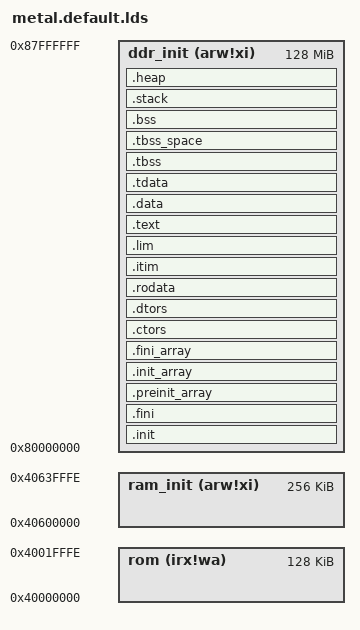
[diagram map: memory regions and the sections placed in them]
/* Copyright (c) 2020 SiFive Inc. */
/* SPDX-License-Identifier: Apache-2.0 */
OUTPUT_ARCH("riscv")

/* Default Linker Script
 *
 * This is the default linker script for all Freedom Metal applications.
 */

ENTRY(_enter)

MEMORY
{
    rom (irx!wa) : ORIGIN = 0x40000000, LENGTH = 0x1ffff
    ram_init (arw!xi) : ORIGIN = 0x40600000, LENGTH = 0x3ffff
    ddr_init (arw!xi) : ORIGIN = 0x80000000, LENGTH = 0x8000000
    /* ram (arw!xi) : ORIGIN = 0x40640000, LENGTH = 0x3bffff */
    /* ddr (arw!xi) : ORIGIN = 0x80040000, LENGTH = 0x7ffbffff */
}

PHDRS
{
    rom PT_LOAD;
    ram_init PT_LOAD;
    ddr_init PT_LOAD;
    /* ddr PT_LOAD; */
    /* tls PT_TLS; */
    /* ram PT_LOAD; */
    text PT_LOAD;
}

SECTIONS
{
    /* Each hart is allocated its own stack of size __stack_size. This value
     * can be overriden at build-time by adding the following to CFLAGS:
     *
     *     -Xlinker --defsym=__stack_size=0xf00
     *
     * where 0xf00 can be replaced with a multiple of 16 of your choice.
     *
     * __stack_size is PROVIDE-ed as a symbol so that initialization code
     * initializes the stack pointers for each hart at the right offset from
     * the _sp symbol.
     */
    __stack_size = DEFINED(__stack_size) ? __stack_size : 0x2000000;
    PROVIDE(__stack_size = __stack_size);

    /* The size of the heap can be overriden at build-time by adding the
     * following to CFLAGS:
     *
     *     -Xlinker --defsym=__heap_size=0xf00
     *
     * where 0xf00 can be replaced with the value of your choice.
     *
     * Altertatively, the heap can be grown to fill the entire remaining region
     * of RAM by adding the following to CFLAGS:
     *
     *     -Xlinker --defsym=__heap_max=1
     *
     * Note that depending on the memory layout, the bitness (32/64bit) of the
     * target, and the code model in use, this might cause a relocation error.
     */
    __heap_size = DEFINED(__heap_size) ? __heap_size : 0x2000000;

    /* The boot hart sets which hart runs the pre-main initialization routines,
     * including copying .data into RAM, zeroing the BSS region, running
     * constructors, etc. After initialization, the boot hart is also the only
     * hart which runs application code unless the application overrides the
     * secondary_main() function to start execution on secondary harts.
     */
    PROVIDE(__metal_boot_hart = 0);

    /* The chicken bit is used by pre-main initialization to enable/disable
     * certain core features */
    PROVIDE(__metal_chicken_bit = 1);

    .init : {
        /* The _enter symbol is placed in the .text.metal.init.enter section
         * and must be placed at the beginning of the program */
        KEEP (*(.text.metal.init.enter))
        KEEP (*(.text.metal.init.*))
        KEEP (*(SORT_NONE(.init)))
        KEEP (*(.text.libgloss.start))
    } >ddr_init :ddr_init

    .fini : {
        KEEP (*(SORT_NONE(.fini)))
    } >ddr_init :ddr_init

    .preinit_array : ALIGN(8) {
        PROVIDE_HIDDEN (__preinit_array_start = .);
        KEEP (*(.preinit_array))
        PROVIDE_HIDDEN (__preinit_array_end = .);
    } >ddr_init :ddr_init

    .init_array : ALIGN(8) {
        PROVIDE_HIDDEN (__init_array_start = .);
        KEEP (*(SORT_BY_INIT_PRIORITY(.init_array.*) SORT_BY_INIT_PRIORITY(.ctors.*)))
        KEEP (*(.init_array EXCLUDE_FILE (*crtbegin.o *crtbegin?.o *crtend.o *crtend?.o ) .ctors))
        PROVIDE_HIDDEN (__init_array_end = .);
        PROVIDE_HIDDEN ( metal_constructors_start = .);
        KEEP (*(SORT_BY_INIT_PRIORITY(.metal.init_array.*)));
        KEEP (*(.metal.init_array));
        PROVIDE_HIDDEN ( metal_constructors_end = .);
    } >ddr_init :ddr_init

    .fini_array : ALIGN(8) {
        PROVIDE_HIDDEN (__fini_array_start = .);
        KEEP (*(SORT_BY_INIT_PRIORITY(.fini_array.*) SORT_BY_INIT_PRIORITY(.dtors.*)))
        KEEP (*(.fini_array EXCLUDE_FILE (*crtbegin.o *crtbegin?.o *crtend.o *crtend?.o ) .dtors))
        PROVIDE_HIDDEN (__fini_array_end = .);
        PROVIDE_HIDDEN ( metal_destructors_start = .);
        KEEP (*(SORT_BY_INIT_PRIORITY(.metal.fini_array.*)));
        KEEP (*(.metal.fini_array));
        PROVIDE_HIDDEN ( metal_destructors_end = .);
    } >ddr_init :ddr_init


    .ctors : {
        KEEP (*crtbegin.o(.ctors))
        KEEP (*crtbegin?.o(.ctors))
        KEEP (*(EXCLUDE_FILE (*crtend.o *crtend?.o ) .ctors))
        KEEP (*(SORT(.ctors.*)))
        KEEP (*(.ctors))
        KEEP (*(.metal.ctors .metal.ctors.*))
    } >ddr_init :ddr_init

    .dtors : {
        KEEP (*crtbegin.o(.dtors))
        KEEP (*crtbegin?.o(.dtors))
        KEEP (*(EXCLUDE_FILE (*crtend.o *crtend?.o ) .dtors))
        KEEP (*(SORT(.dtors.*)))
        KEEP (*(.dtors))
        KEEP (*(.metal.dtors .metal.dtors.*))
    } >ddr_init : ddr_init

    .rodata : {
        *(.rdata)
        *(.rodata .rodata.*)
        *(.gnu.linkonce.r.*)
        . = ALIGN(8);
        *(.srodata.cst16)
        *(.srodata.cst8)
        *(.srodata.cst4)
        *(.srodata.cst2)
        *(.srodata .srodata.*)
    } >ddr_init :ddr_init

    .itim : ALIGN(8) {
        *(.itim .itim.*)
    } >ddr_init :ddr_init

    PROVIDE( metal_segment_itim_source_start = LOADADDR(.itim) );
    PROVIDE( metal_segment_itim_target_start = ADDR(.itim) );
    PROVIDE( metal_segment_itim_target_end = ADDR(.itim) + SIZEOF(.itim) );
    
    .lim : ALIGN(8) {
        *(.lim .lim.*)
    } >ddr_init :ddr_init

    PROVIDE( metal_segment_lim_source_start = LOADADDR(.lim) );
    PROVIDE( metal_segment_lim_target_start = ADDR(.lim) );
    PROVIDE( metal_segment_lim_target_end = ADDR(.lim) + SIZEOF(.lim) );
    
    .text : {
        *(.text.unlikely .text.unlikely.*)
        *(.text.startup .text.startup.*)
        *(.text .text.*)
        *(.gnu.linkonce.t.*)
    } >ddr_init :text

    .data : ALIGN(8) {
        *(.data .data.*)
        *(.gnu.linkonce.d.*)
        . = ALIGN(8);
        PROVIDE( __global_pointer$ = . + 0x800 );
        *(.sdata .sdata.* .sdata2.*)
        *(.gnu.linkonce.s.*)
    } >ddr_init :ddr_init

    .tdata : ALIGN(8) {
        PROVIDE( __tls_base = . );
	*(.tdata .tdata.* .gnu.linkonce.td.*)
    } >ddr_init :ddr_init

    PROVIDE( __tdata_source = LOADADDR(.tdata) );
    PROVIDE( __tdata_size = SIZEOF(.tdata) );

    PROVIDE( metal_segment_data_source_start = LOADADDR(.data) );
    PROVIDE( metal_segment_data_target_start = ADDR(.data) );
    PROVIDE( metal_segment_data_target_end = ADDR(.tdata) + SIZEOF(.tdata) );

    .tbss : ALIGN(8) {
	*(.tbss .tbss.* .gnu.linkonce.tb.*)
	*(.tcommon .tcommon.*)
	PROVIDE( __tls_end = . );
    } >ddr_init :ddr_init
    
    PROVIDE( __tbss_size = SIZEOF(.tbss) );
    PROVIDE( __tls_size = __tls_end - __tls_base );

    .tbss_space : ALIGN(8) {
	. = . + __tbss_size;
    } >ddr_init :ddr_init

    .bss (NOLOAD): ALIGN(8) {
        *(.sbss*)
        *(.gnu.linkonce.sb.*)
        *(.bss .bss.*)
        *(.gnu.linkonce.b.*)
        *(COMMON)
    } >ddr_init :ddr_init

    PROVIDE( metal_segment_bss_source_start = LOADADDR(.tbss) );
    PROVIDE( metal_segment_bss_target_start = ADDR(.tbss) );
    PROVIDE( metal_segment_bss_target_end = ADDR(.bss) + SIZEOF(.bss) );

    .stack (NOLOAD) : ALIGN(8) {
        PROVIDE(metal_segment_stack_begin = .);
        . += __stack_size; /* Hart 0 */
        PROVIDE( _sp = . );
        PROVIDE(metal_segment_stack_end = .);
    } >ddr_init :ddr_init

    .heap (NOLOAD) : ALIGN(8) {
        PROVIDE( __end = . );
        PROVIDE( __heap_start = . );
        PROVIDE( metal_segment_heap_target_start = . );
        /* If __heap_max is defined, grow the heap to use the rest of RAM,
         * otherwise set the heap size to __heap_size */
        . = DEFINED(__heap_max) ? MIN( LENGTH(ddr_init) - ( . - ORIGIN(ddr_init)) , 0x2000000) : __heap_size;
        PROVIDE( metal_segment_heap_target_end = . );
        PROVIDE( _heap_end = . );
        PROVIDE( __heap_end = . );
    } >ddr_init :ddr_init

    /* C++ exception handling information is
     * not useful with our current runtime environment,
     * and it consumes flash space. Discard it until
     * we have something that can use it
     */
    /DISCARD/ : {
	*(.eh_frame .eh_frame.*)
    }
}
